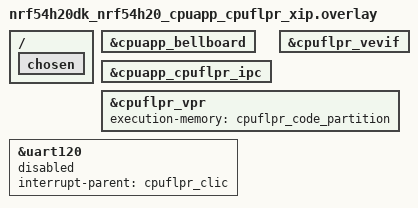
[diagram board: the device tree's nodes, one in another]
/*
 * Copyright (c) 2025 Nordic Semiconductor ASA
 *
 * SPDX-License-Identifier: Apache-2.0
 */

 /* Setup for cpuapp_cpuflpr_ipc */
&cpuapp_bellboard {
	status = "okay";
};

/delete-node/ &cpuapp_cpurad_ipc;

ipc0: &cpuapp_cpuflpr_ipc {
	status = "okay";
};

&cpuflpr_vevif {
	status = "okay";
};

/ {
	chosen {
		/delete-property/ zephyr,bt-hci;
	};
};

/* Necessary for the cpuflpr_xip to work */
&cpuflpr_vpr {
	status = "okay";
	execution-memory = <&cpuflpr_code_partition>;
	/delete-property/ source-memory;
};

&uart120 {
	status = "reserved";
	interrupt-parent = <&cpuflpr_clic>;
};
